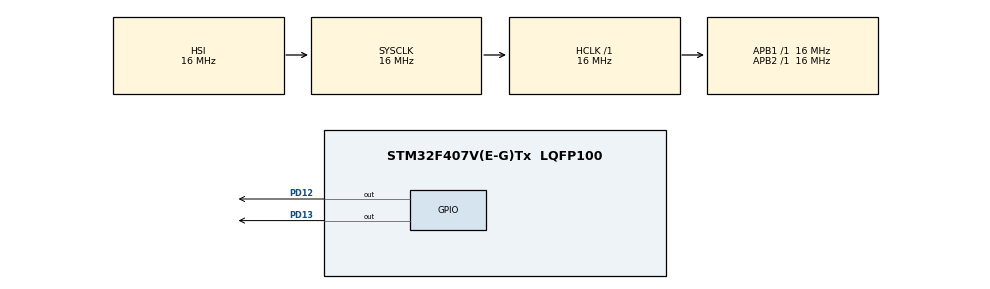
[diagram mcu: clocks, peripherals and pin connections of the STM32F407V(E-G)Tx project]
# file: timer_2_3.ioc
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Mcu.Family=STM32F4
Mcu.Name=STM32F407V(E-G)Tx
Mcu.Package=LQFP100
NVIC.PriorityGroup=NVIC_PRIORITYGROUP_4
NVIC.TIM2_IRQn=true\:0\:0\:false\:false\:true\:true\:true\:true
NVIC.TIM3_IRQn=true\:0\:0\:false\:false\:true\:true\:true\:true
PD12.Signal=GPIO_Output
PD13.Signal=GPIO_Output
ProjectManager.HeapSize=0x200
ProjectManager.StackSize=0x400
ProjectManager.TargetToolchain=STM32CubeIDE
RCC.AHBFreq_Value=16000000
RCC.APB1Freq_Value=16000000
RCC.APB2Freq_Value=16000000
RCC.CortexFreq_Value=16000000
RCC.HSE_VALUE=25000000
RCC.HSI_VALUE=16000000
RCC.LSE_VALUE=32768
RCC.SYSCLKFreq_VALUE=16000000
RCC.VCOOutputFreq_Value=192000000
TIM2.Period=2000
TIM2.Prescaler=16000
TIM2.TIM_MasterOutputTrigger=TIM_TRGO_UPDATE
TIM3.Period=5000
TIM3.Prescaler=16000
TIM3.TIM_MasterOutputTrigger=TIM_TRGO_UPDATE
VP_TIM2_VS_ClockSourceINT.Mode=Internal
VP_TIM3_VS_ClockSourceINT.Mode=Internal
board=custom

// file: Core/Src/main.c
/* USER CODE BEGIN Header */
/**
  ******************************************************************************
  * @file           : main.c
  * @brief          : Main program body
  ******************************************************************************
  * @attention
  *
  * Copyright (c) 2023 STMicroelectronics.
  * All rights reserved.
  *
  * This software is licensed under terms that can be found in the LICENSE file
  * in the root directory of this software component.
  * If no LICENSE file comes with this software, it is provided AS-IS.
  *
  ******************************************************************************
  */
/* USER CODE END Header */
#include "main.h"

TIM_HandleTypeDef htim2;
TIM_HandleTypeDef htim3;
uint32_t counter1;
uint32_t counter2;

void SystemClock_Config(void);
static void MX_GPIO_Init(void);
static void MX_TIM2_Init(void);
static void MX_TIM3_Init(void);

int main(void)
{

  /* MCU Configuration--------------------------------------------------------*/

  /* Reset of all peripherals, Initializes the Flash interface and the Systick. */
  HAL_Init();

  /* Configure the system clock */
  SystemClock_Config();

  /* Initialize all configured peripherals */
  MX_GPIO_Init();
  MX_TIM2_Init();
  MX_TIM3_Init();
  /* USER CODE BEGIN 2 */
   HAL_TIM_Base_Start_IT(&htim2);
   HAL_TIM_Base_Start_IT(&htim3);
  /* USER CODE END 2 */

  /* Infinite loop */
  /* USER CODE BEGIN WHILE */
  while (1)
  {    counter1=__HAL_TIM_GetCounter(&htim2);
       counter2=__HAL_TIM_GetCounter(&htim3);
    /* USER CODE END WHILE */

  }
}

void SystemClock_Config(void)
{
  RCC_OscInitTypeDef RCC_OscInitStruct = {0};
  RCC_ClkInitTypeDef RCC_ClkInitStruct = {0};

  /** Configure the main internal regulator output voltage
  */
  __HAL_RCC_PWR_CLK_ENABLE();
  __HAL_PWR_VOLTAGESCALING_CONFIG(PWR_REGULATOR_VOLTAGE_SCALE1);

  /** Initializes the RCC Oscillators according to the specified parameters
  * in the RCC_OscInitTypeDef structure.
  */
  RCC_OscInitStruct.OscillatorType = RCC_OSCILLATORTYPE_HSI;
  RCC_OscInitStruct.HSIState = RCC_HSI_ON;
  RCC_OscInitStruct.HSICalibrationValue = RCC_HSICALIBRATION_DEFAULT;
  RCC_OscInitStruct.PLL.PLLState = RCC_PLL_NONE;
  if (HAL_RCC_OscConfig(&RCC_OscInitStruct) != HAL_OK)
  {
    Error_Handler();
  }

  /** Initializes the CPU, AHB and APB buses clocks
  */
  RCC_ClkInitStruct.ClockType = RCC_CLOCKTYPE_HCLK|RCC_CLOCKTYPE_SYSCLK
                              |RCC_CLOCKTYPE_PCLK1|RCC_CLOCKTYPE_PCLK2;
  RCC_ClkInitStruct.SYSCLKSource = RCC_SYSCLKSOURCE_HSI;
  RCC_ClkInitStruct.AHBCLKDivider = RCC_SYSCLK_DIV1;
  RCC_ClkInitStruct.APB1CLKDivider = RCC_HCLK_DIV1;
  RCC_ClkInitStruct.APB2CLKDivider = RCC_HCLK_DIV1;

  if (HAL_RCC_ClockConfig(&RCC_ClkInitStruct, FLASH_LATENCY_0) != HAL_OK)
  {
    Error_Handler();
  }
}

static void MX_TIM2_Init(void)
{

  TIM_ClockConfigTypeDef sClockSourceConfig = {0};
  TIM_MasterConfigTypeDef sMasterConfig = {0};

  htim2.Instance = TIM2;
  htim2.Init.Prescaler = 16000;
  htim2.Init.CounterMode = TIM_COUNTERMODE_UP;
  htim2.Init.Period = 2000;
  htim2.Init.ClockDivision = TIM_CLOCKDIVISION_DIV1;
  htim2.Init.AutoReloadPreload = TIM_AUTORELOAD_PRELOAD_DISABLE;
  if (HAL_TIM_Base_Init(&htim2) != HAL_OK)
  {
    Error_Handler();
  }
  sClockSourceConfig.ClockSource = TIM_CLOCKSOURCE_INTERNAL;
  if (HAL_TIM_ConfigClockSource(&htim2, &sClockSourceConfig) != HAL_OK)
  {
    Error_Handler();
  }
  sMasterConfig.MasterOutputTrigger = TIM_TRGO_UPDATE;
  sMasterConfig.MasterSlaveMode = TIM_MASTERSLAVEMODE_DISABLE;
  if (HAL_TIMEx_MasterConfigSynchronization(&htim2, &sMasterConfig) != HAL_OK)
  {
    Error_Handler();
  }

}

static void MX_TIM3_Init(void)
{

  TIM_ClockConfigTypeDef sClockSourceConfig = {0};
  TIM_MasterConfigTypeDef sMasterConfig = {0};

  htim3.Instance = TIM3;
  htim3.Init.Prescaler = 16000;
  htim3.Init.CounterMode = TIM_COUNTERMODE_UP;
  htim3.Init.Period = 5000;
  htim3.Init.ClockDivision = TIM_CLOCKDIVISION_DIV1;
  htim3.Init.AutoReloadPreload = TIM_AUTORELOAD_PRELOAD_DISABLE;
  if (HAL_TIM_Base_Init(&htim3) != HAL_OK)
  {
    Error_Handler();
  }
  sClockSourceConfig.ClockSource = TIM_CLOCKSOURCE_INTERNAL;
  if (HAL_TIM_ConfigClockSource(&htim3, &sClockSourceConfig) != HAL_OK)
  {
    Error_Handler();
  }
  sMasterConfig.MasterOutputTrigger = TIM_TRGO_UPDATE;
  sMasterConfig.MasterSlaveMode = TIM_MASTERSLAVEMODE_DISABLE;
  if (HAL_TIMEx_MasterConfigSynchronization(&htim3, &sMasterConfig) != HAL_OK)
  {
    Error_Handler();
  }

}

static void MX_GPIO_Init(void)
{
  GPIO_InitTypeDef GPIO_InitStruct = {0};

  /* GPIO Ports Clock Enable */
  __HAL_RCC_GPIOD_CLK_ENABLE();

  /*Configure GPIO pin Output Level */
  HAL_GPIO_WritePin(GPIOD, GPIO_PIN_12|GPIO_PIN_13, GPIO_PIN_RESET);

  /*Configure GPIO pins : PD12 PD13 */
  GPIO_InitStruct.Pin = GPIO_PIN_12|GPIO_PIN_13;
  GPIO_InitStruct.Mode = GPIO_MODE_OUTPUT_PP;
  GPIO_InitStruct.Pull = GPIO_NOPULL;
  GPIO_InitStruct.Speed = GPIO_SPEED_FREQ_LOW;
  HAL_GPIO_Init(GPIOD, &GPIO_InitStruct);

}

/* USER CODE BEGIN 4 */
void HAL_TIM_PeriodElapsedCallback(TIM_HandleTypeDef *htim)
{
  if(htim->Instance == TIM2){
  HAL_GPIO_TogglePin(GPIOD, GPIO_PIN_12);
  }
  if(htim->Instance == TIM3){
    HAL_GPIO_TogglePin(GPIOD, GPIO_PIN_13);
}
}
/* USER CODE END 4 */

void Error_Handler(void)
{
  __disable_irq();
  while (1)
  {
  }
}
